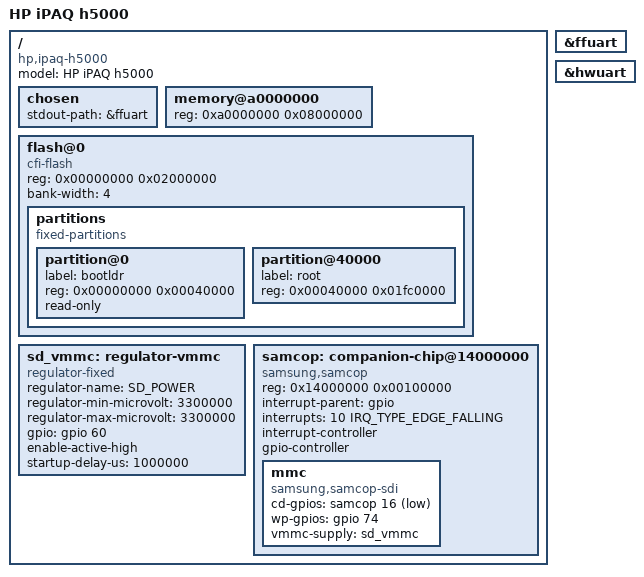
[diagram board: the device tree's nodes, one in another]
// SPDX-License-Identifier: GPL-2.0-only
/*
 * Device tree for the HP iPAQ h51xx/h54xx/h55xx handheld family
 * (h5150/h5450/h5455/h5550/h5555 and siblings -- one board design,
 * three RAM/flash/SoC configurations).
 *
 * Named pxa250-* despite h51xx/h55xx being PXA255, following the
 * pxa250-hp-ipaq-h2200.dts precedent: "marvell,pxa250" is the only
 * string pxa25x_dt_board_compat[] (arch/arm/mach-pxa/pxa-dt.c) and
 * pxa25x.dtsi both advertise, so it is the mandatory fallback
 * compatible regardless of which PXA25x part is actually fitted.
 * cpu_is_pxa255() at runtime (include/linux/soc/pxa/cpu.h) is how
 * board code tells the two apart.
 *
 * The memory node describes the 128 MiB of the h55xx. The h51xx and
 * h54xx have 64 MiB and must not inherit this value. The boot loader is
 * ATAGS-only, so the board boots from an appended DTB with
 * ARM_ATAG_DTB_COMPAT, which lets the boot loader's ATAG_MEM replace the
 * reg property (arch/arm/boot/compressed/atags_to_fdt.c).
 *
 * Every pad except the ones the pin controller owns is muxed by the
 * pxa2xx_mfp_config() table in arch/arm/mach-pxa/h5000.c, applied from an
 * of_machine_is_compatible() gated initcall because the generic PXA25x DT
 * machine has no per-board hook.
 *
 * pxa25x.dtsi has no static memory controller node or chip-select
 * ranges, so the devices on the static chip selects are described at
 * their raw physical addresses.
 *
 * Copyright (C) 2026 Koen Kooi
 */

/dts-v1/;

#include <dt-bindings/gpio/gpio.h>
#include <dt-bindings/interrupt-controller/irq.h>

#include "pxa25x.dtsi"

/ {
	model = "HP iPAQ h5000";
	compatible = "hp,ipaq-h5000", "marvell,pxa250";

	chosen {
		stdout-path = &ffuart;
	};

	memory@a0000000 {
		device_type = "memory";
		reg = <0xa0000000 0x08000000>; /* 128 MiB, h55xx */
	};

	/*
	 * NOR flash on nCS_0. The CFI probe of the fitted part finds 32 MiB
	 * (0x00000000-0x01ffffff). Vendor sources describe a further 16 MiB
	 * bank at 0x02000000 on h54xx/h55xx, but it has not been probed on
	 * live hardware, so it is not described here: probing a bank that
	 * is absent can alias bank 0, and a partition on that alias would
	 * then write over the boot loader.
	 *
	 * The partitions come from this node rather than from the boot
	 * loader's mtdparts= argument, because cmdlinepart matches the mtd_id
	 * of that argument ("ipaq") against the device name ("0.flash") and
	 * so never applies.
	 */
	flash@0 {
		compatible = "cfi-flash";
		reg = <0x00000000 0x02000000>;
		bank-width = <4>;

		#address-cells = <1>;
		#size-cells = <1>;

		partitions {
			compatible = "fixed-partitions";
			#address-cells = <1>;
			#size-cells = <1>;

			partition@0 {
				label = "bootldr";
				reg = <0x00000000 0x00040000>;
				read-only;
			};

			partition@40000 {
				label = "root";
				reg = <0x00040000 0x01fc0000>;
			};
		};
	};

	/*
	 * Internal SD slot power switch, PXA GPIO60. The "_N" in the vendor
	 * header name (H5000_GPIO_POWER_SD_N) is a misnomer, the pin is active
	 * high. It is a DT regulator and not a board-file platform device so
	 * that fw_devlink orders the SD host's probe after it: the regulator
	 * core's optional supply lookup never defers, so a host that probed
	 * first found no supply for good and the settle delay below never ran.
	 *
	 * enable-active-high, not the phandle flag, sets the polarity of a
	 * regulator-fixed gpio; GPIO_ACTIVE_HIGH is written on the phandle for
	 * readability. No regulator-boot-on: the pad is muxed driving low, so
	 * the rail is off at reset.
	 *
	 * The factory firmware's slot power-up waits a full second before the
	 * first SD command, and boots without an equivalent delay never saw
	 * ACMD41 report ready. startup-delay-us carries that second.
	 */
	sd_vmmc: regulator-vmmc {
		compatible = "regulator-fixed";
		regulator-name = "SD_POWER";
		regulator-min-microvolt = <3300000>;
		regulator-max-microvolt = <3300000>;
		gpio = <&gpio 60 GPIO_ACTIVE_HIGH>;
		enable-active-high;
		startup-delay-us = <1000000>;
	};

	/*
	 * SAMCOP companion ASIC on nCS_5 (PXA_CS5_PHYS). The window is the
	 * chip's own 1 MiB register space. Its single upstream interrupt,
	 * ASIC_INT_N, is PXA GPIO10, active low, caught on the falling edge.
	 * The chip is both the interrupt controller and the GPIO controller
	 * for the peripherals behind it.
	 */
	samcop: companion-chip@14000000 {
		compatible = "samsung,samcop";
		reg = <0x14000000 0x00100000>;

		interrupt-parent = <&gpio>;
		interrupts = <10 IRQ_TYPE_EDGE_FALLING>;

		interrupt-controller;
		#interrupt-cells = <2>;

		gpio-controller;
		#gpio-cells = <2>;

		/*
		 * The SD/MMC slot. cd-gpios is SAMCOP GPA16, active low (pin
		 * low = card present), muxed to EXTIN and pulled up by the MFD
		 * core. The matching edge interrupt is the cell's own second IRQ
		 * resource, because GPA16 is not in the GPIO interrupt map.
		 *
		 * wp-gpios is PXA GPIO74, active high despite the vendor name
		 * (H5000_GPIO_SD_WP_N): the factory SD driver reads GPLR2 bit 10
		 * and reports the card write-protected when the pin reads high,
		 * which also matches the usual socket wiring of a switch opened
		 * by the locked tab with the line pulled up. Active low would
		 * make every unlocked card read-only. The polarity has not been
		 * checked on hardware with a locked card.
		 *
		 * Slot power is the sd_vmmc regulator, a supply and not a gpiod
		 * lookup.
		 */
		mmc {
			compatible = "samsung,samcop-sdi";
			cd-gpios = <&samcop 16 GPIO_ACTIVE_LOW>;
			wp-gpios = <&gpio 74 GPIO_ACTIVE_HIGH>;
			vmmc-supply = <&sd_vmmc>;
		};
	};
};

&ffuart {
	status = "okay";
};

/*
 * The onboard Bluetooth (LMX9814) is on the HWUART pins GPIO42-45, not
 * on the BTUART, so the BTUART stays disabled: both would drive the same
 * pads.
 */
&hwuart {
	status = "okay";
};
